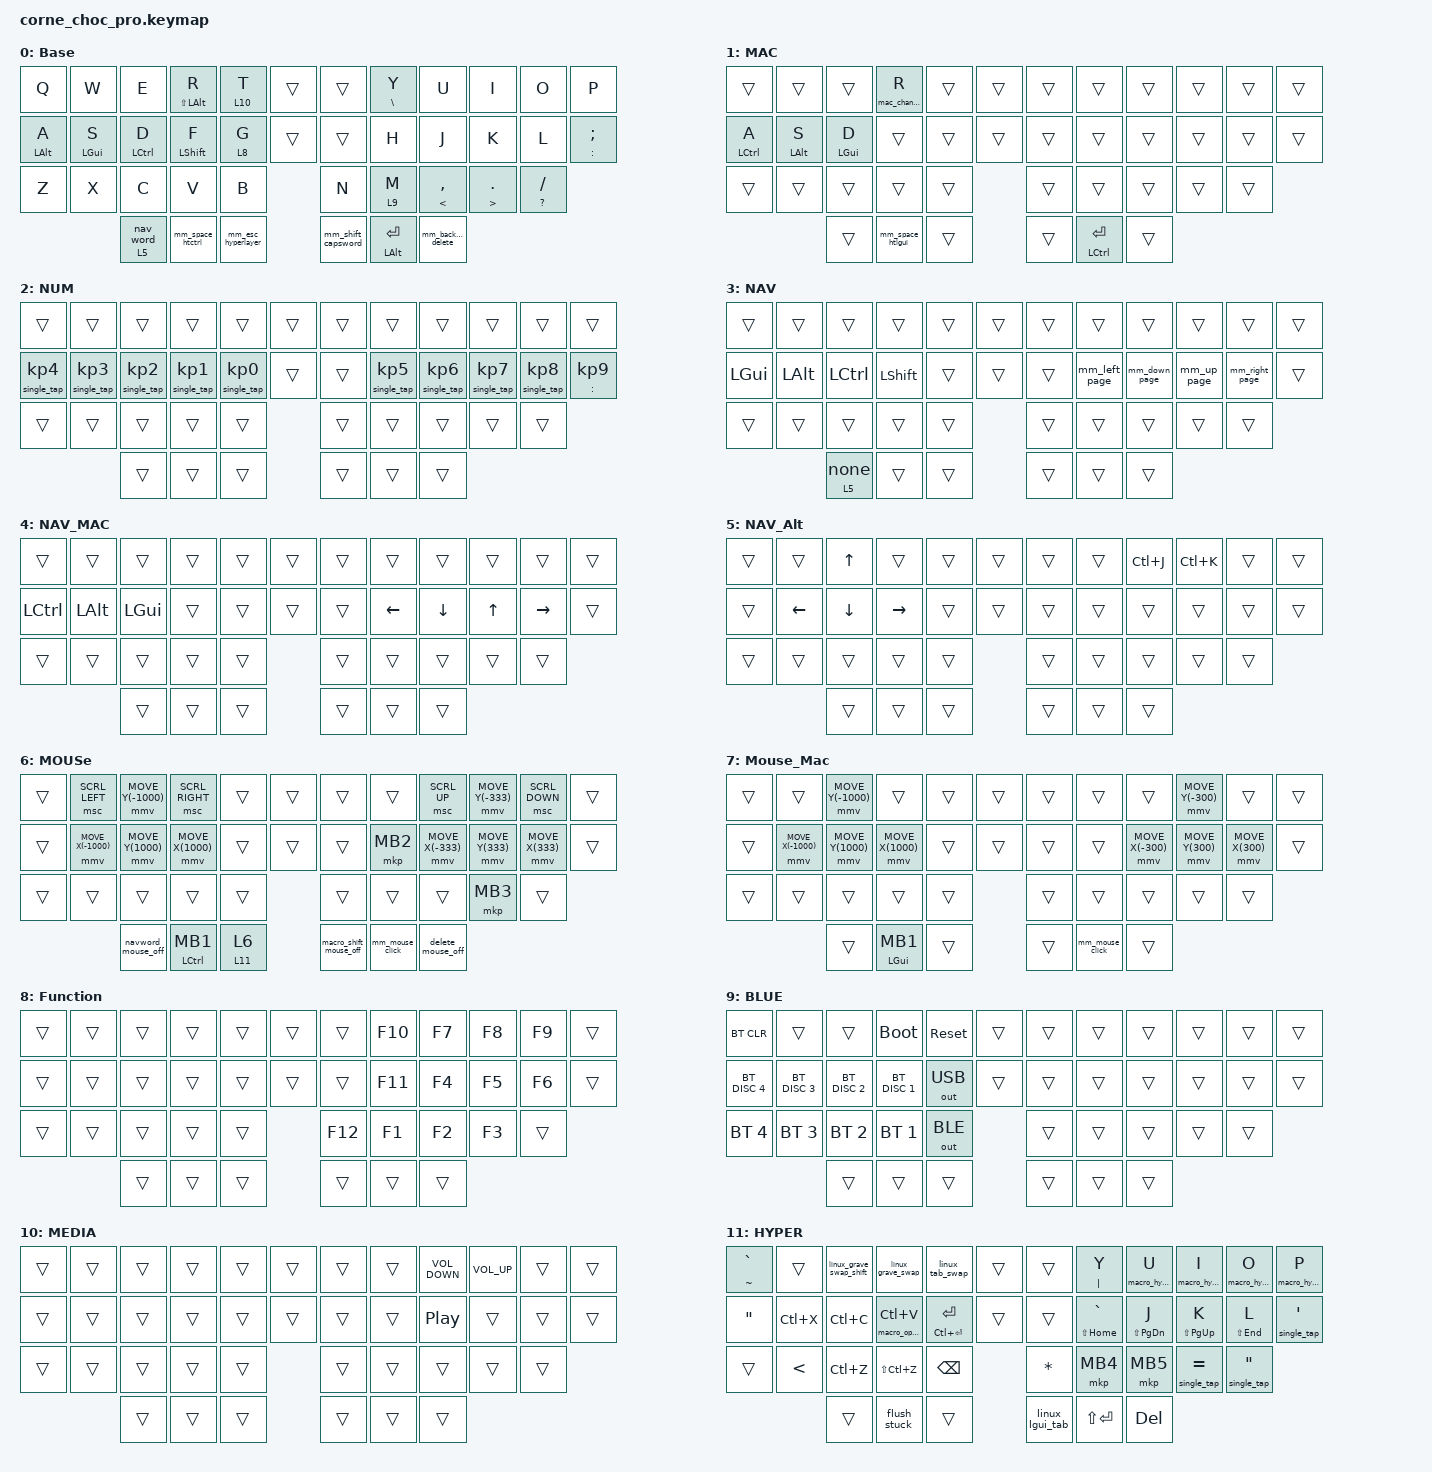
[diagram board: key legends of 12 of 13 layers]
/*
 * Copyright (c) 2020 The ZMK Contributors
 *
 * SPDX-License-Identifier: MIT
 */

#define ZMK_POINTING_DEFAULT_MOVE_VAL 1000  // default: 600
#define ZMK_POINTING_DEFAULT_SCRL_VAL 20    // default: 10
#define NUM 2
#define NAV 3

#include <behaviors.dtsi>
#include <dt-bindings/zmk/bt.h>
#include <dt-bindings/zmk/keys.h>
#include <dt-bindings/zmk/outputs.h>
#include <dt-bindings/zmk/pointing.h>
#include <dt-bindings/zmk/rgb.h>

&sk {
    release-after-ms = <1500>;
    quick-release;
};

&mmv {
    time-to-max-speed-ms = <2>;
    acceleration-exponent = <3>;
};

&msc {
    delay-ms = <0>;
    acceleration-exponent = <3>;
    time-to-max-speed-ms = <1>;
};

/ {
    chosen { zmk,physical-layout = &five_col_layout; };
};

/ {
    macros {
        mouse_mode_color_on: mouse_mode_color {
            compatible = "zmk,behavior-macro";
            #binding-cells = <0>;
            bindings = <&macro_tap>, <&tog 6>;

            label = "MOUSE_MODE_COLOR";
        };

        macro_mo2AndLshft: smart_tab_shift {
            compatible = "zmk,behavior-macro";
            #binding-cells = <0>;
            bindings =
                <&macro_press>,
                <&mo 2 &kp LSHIFT>,
                <&macro_pause_for_release>,
                <&macro_release>,
                <&mo 2 &kp LEFT_SHIFT>;

            label = "SMART_TAB_SHIFT";
        };

        mouse_mode_off: mouse_mode_color_off {
            compatible = "zmk,behavior-macro";
            #binding-cells = <0>;
            bindings = <&macro_tap>, <&tog 6>;

            label = "MOUSE_MODE_COLOR";
        };

        mac_lgui_tab: mac_lgui_tab {
            compatible = "zmk,behavior-macro";
            #binding-cells = <0>;
            bindings =
                <&macro_press>,
                <&kp LEFT_GUI>,
                <&macro_tap>,
                <&kp TAB>,
                <&macro_release>,
                <&kp LEFT_GUI>;

            label = "MAC_LGUI_TAB";
        };

        mac_lgui_tab_double: mac_lgui_tab_double {
            compatible = "zmk,behavior-macro";
            #binding-cells = <0>;
            bindings =
                <&macro_press>,
                <&kp LEFT_GUI>,
                <&macro_tap>,
                <&kp TAB>,
                <&macro_tap>,
                <&kp TAB>,
                <&macro_release>,
                <&kp LEFT_GUI>;

            label = "MAC_LGUI_TAB_DOUBLE";
        };

        mac_lgui_tab_tripple: mac_lgui_tab_tripple {
            compatible = "zmk,behavior-macro";
            #binding-cells = <0>;
            bindings =
                <&macro_press>,
                <&kp LEFT_GUI>,
                <&macro_tap>,
                <&kp TAB>,
                <&macro_tap>,
                <&kp TAB>,
                <&macro_tap>,
                <&kp TAB>,
                <&macro_release>,
                <&kp LEFT_GUI>;

            label = "MAC_LGUI_TAB_TRIPPLE";
        };

        linux_lgui_tab: linux_lgui_tab {
            compatible = "zmk,behavior-macro";
            #binding-cells = <0>;
            bindings =
                <&macro_press>,
                <&kp LALT>,
                <&macro_tap>,
                <&kp TAB>,
                <&macro_release>,
                <&kp LALT>;

            label = "LINUX_LGUI_TAB";
        };

        linux_lgui_tab_double: linux_lgui_tab_double {
            compatible = "zmk,behavior-macro";
            #binding-cells = <0>;
            bindings =
                <&macro_press>,
                <&kp LALT>,
                <&macro_tap>,
                <&kp TAB>,
                <&macro_tap>,
                <&kp TAB>,
                <&macro_release>,
                <&kp LALT>;

            label = "LINUX_LGUI_TAB_DOUBLE";
        };

        linux_lgui_tab_tripple: linux_lgui_tab_tripple {
            compatible = "zmk,behavior-macro";
            #binding-cells = <0>;
            bindings =
                <&macro_press>,
                <&kp LALT>,
                <&macro_tap>,
                <&kp TAB>,
                <&macro_tap>,
                <&kp TAB>,
                <&macro_tap>,
                <&kp TAB>,
                <&macro_release>,
                <&kp LALT>;

            label = "LINUX_LGUI_TAB_TRIPPLE";
        };

        mac_change_language: mac_change_language {
            compatible = "zmk,behavior-macro";
            #binding-cells = <0>;
            bindings = <&kp LC(SPC)>;
            label = "MAC_CHANGE_LANGUAGE";
        };

        macro_open_clipboard: macro_open_clipboard {
            compatible = "zmk,behavior-macro";
            #binding-cells = <0>;
            bindings =
                <&macro_press>,
                <&kp LCTRL &kp LGUI>,
                <&macro_tap>,
                <&kp C>,
                <&macro_release>,
                <&kp LCTRL &kp LGUI>;

            label = "MACRO_OPEN_CLIPBOARD";
        };

        mouse_click_and_off: mouse_click_and_off {
            compatible = "zmk,behavior-macro";
            #binding-cells = <0>;
            bindings =
                <&macro_tap>,
                <&macro_color_off>,
                <&macro_tap>,
                <&mkp MB1 &tog 6>;

            label = "MOUSE_CLICK_AND_OFF";
        };

        macro_color_off: macro_color_off {
            compatible = "zmk,behavior-macro";
            #binding-cells = <0>;
            bindings = <&macro_tap>;
            label = "MACRO_COLOR_OFF";
        };

        macro_mouse_up: macro_mouse_up {
            compatible = "zmk,behavior-macro";
            #binding-cells = <0>;
            bindings =
                <&macro_press>,
                <&mmv MOVE_Y(-300) &sl 0>,
                <&macro_pause_for_release>,
                <&macro_release>,
                <&mmv MOVE_Y(-300) &sl 0>;

            label = "MACRO_MOUSE_UP";
        };

        macro_color_on: macro_color_on {
            compatible = "zmk,behavior-macro";
            #binding-cells = <0>;
            bindings = <&macro_tap>, <&rgb_ug RGB_ON>;

            label = "MACRO_COLOR_ON";
        };

        flush_stuck: flush_stuck {
            compatible = "zmk,behavior-macro";
            #binding-cells = <0>;
            bindings =
                <&macro_release>,
                <&kp LCTRL>,
                <&macro_release>,
                <&kp LEFT_SHIFT>,
                <&macro_release>,
                <&kp LEFT_ALT>,
                <&macro_release>,
                <&kp LEFT_GUI>,
                <&macro_release>,
                <&kp RCTRL>,
                <&macro_release>,
                <&kp RIGHT_SHIFT>,
                <&macro_release>,
                <&kp RIGHT_ALT>,
                <&macro_release>,
                <&kp RIGHT_GUI>;

            label = "FLUSH_STUCK";
        };

        navword_mouse_off: test {
            compatible = "zmk,behavior-macro";
            #binding-cells = <0>;
            bindings = <&macro_tap>, <&tog 6>, <&macro_tap>, <&nav_word>;

            label = "NAVWORD_NOUSE_OFF";
        };

        delete_mouse_off: delete_mouse_off {
            compatible = "zmk,behavior-macro";
            #binding-cells = <0>;
            bindings = <&macro_tap>, <&tog 6>, <&macro_tap>, <&kp BACKSPACE>;

            label = "DELETE_MOUSE_OFF";
        };

        single_tap: single_tap {
            compatible = "zmk,behavior-macro-one-param";
            #binding-cells = <1>;
            bindings =
                <&macro_param_1to1>,
                <&macro_tap>,
                <&kp MACRO_PLACEHOLDER>,
                <&macro_wait_time 200>;

            label = "SINGLE_TAP";
        };

        hyper_and_mouse_off: hyper_and_mouse_off {
            compatible = "zmk,behavior-macro";
            #binding-cells = <0>;
            bindings =
                <&macro_tap>,
                <&tog 6>,
                <&macro_press>,
                <&kp LS(LA(LC(LG(LGUI))))>,
                <&macro_pause_for_release>,
                <&macro_release>,
                <&kp LS(LA(LC(LG(LEFT_GUI))))>,
                <&macro_tap>,
                <&tog 6>;

            label = "HYPER_AND_MOUSE_OFF";
        };

        macro_hold_and_mouse_off: ht_mouse_off {
            compatible = "zmk,behavior-macro-one-param";
            #binding-cells = <1>;
            bindings =
                <&macro_tap>,
                <&tog 6>,
                <&macro_press>,
                <&macro_param_1to1 &kp MACRO_PLACEHOLDER>,
                <&macro_release>,
                <&macro_param_1to1 &kp MACRO_PLACEHOLDER>;

            label = "HT_MOUSE_OFF";
        };

        mm_shift_capsword: mm_shift_capsword {
            compatible = "zmk,behavior-mod-morph";
            label = "MM_SHIFT_CAPSWORD";
            bindings =
                <&ht_sk_shift_capsword LEFT_SHIFT LEFT_SHIFT>,
                <&caps_word>;

            #binding-cells = <0>;
            mods = <(MOD_LSFT)>;
        };

        macro_shift_mouse_off: macro_sticky_and_mouse_off {
            compatible = "zmk,behavior-macro";
            #binding-cells = <0>;
            bindings =
                <&macro_tap>,
                <&tog 6>,
                <&macro_tap>,
                <&mm_shift_capsword>;

            label = "MACRO_STICKY_AND_MOUSE_OFF";
        };

        num_single_tap: num_single_tap {
            compatible = "zmk,behavior-macro-one-param";
            #binding-cells = <1>;
            bindings =
                <&macro_tap>,
                <&num_word &macro_param_1to1>,
                <&macro_tap>,
                <&kp MACRO_PLACEHOLDER>,
                <&macro_wait_time 200>;

            label = "NUM_SINGLE_TAP";
        };

        macro_hyperkey: macro_hyperkey {
            compatible = "zmk,behavior-macro-one-param";
            #binding-cells = <1>;
            bindings =
                <&macro_press>,
                <&kp LS(LA(LC(LG(LGUI)))) &macro_param_1to1>,
                <&macro_tap>,
                <&kp MACRO_PLACEHOLDER>,
                <&macro_pause_for_release>,
                <&macro_release>,
                <&kp LS(LA(LC(LG(LGUI))))>;

            label = "MACRO_HYPERKEY";
        };

        macro_tap_on_release: macro_tap_release {
            compatible = "zmk,behavior-macro-one-param";
            #binding-cells = <1>;
            bindings =
                <&macro_press>,
                <&macro_pause_for_release>,
                <&macro_release>,
                <&macro_tap>,
                <&macro_param_1to1 &kp MACRO_PLACEHOLDER>;

            label = "MACRO_TAP_RELEASE";
        };

        macro_select_line: macro_select_line {
            compatible = "zmk,behavior-macro";
            #binding-cells = <0>;
            bindings =
                <&macro_press>,
                <&kp LGUI>,
                <&macro_tap>,
                <&kp LEFT>,
                <&macro_press>,
                <&kp LSHIFT>,
                <&macro_tap>,
                <&kp RIGHT>,
                <&macro_pause_for_release>,
                <&macro_release>,
                <&kp LEFT_GUI &kp LSHIFT>,
                <&macro_tap>,
                <&kp LG(C)>;

            label = "MACRO_SELECT_LINE";
        };

        macro_mo_nav_heavy_and_tap: macro_mt_and_tap_on_release {
            compatible = "zmk,behavior-macro-one-param";
            #binding-cells = <1>;
            bindings =
                <&macro_press>,
                <&mo 4>,
                <&macro_pause_for_release>,
                <&macro_release>,
                <&mo 4>,
                <&macro_tap>,
                <&macro_param_1to1 &kp MACRO_PLACEHOLDER>;

            label = "MACRO_MT_AND_TAP_ON_RELEASE";
        };
    };

    combos {
        compatible = "zmk,combos";

        combo_toggle_base_mac {
            bindings = <&tog 1>;
            key-positions = <8 9 10>;
            layers = <0 6 1 7>;
        };

        mac_screenshot_clipboard {
            bindings = <&kp LS(LC(LG(NUMBER_4)))>;
            key-positions = <12 24>;
        };

        combo_left_bracket {
            bindings = <&single_tap LEFT_BRACKET>;
            key-positions = <14 15>;
            layers = <0 1>;
        };

        combo_right_bracket {
            bindings = <&single_tap RIGHT_BRACKET>;
            key-positions = <20 21>;
            layers = <0 1 3 4>;
        };

        combo_paren_left {
            bindings = <&single_tap LEFT_PARENTHESIS>;
            key-positions = <15 16>;
            layers = <0 1>;
        };

        combo_parent_right {
            bindings = <&single_tap RIGHT_PARENTHESIS>;
            key-positions = <19 20>;
            layers = <0 1>;
        };

        combo_tog_mouse {
            bindings = <&mouse_mode_color_on>;
            key-positions = <20 9>;
            layers = <0 1 2 8>;
        };

        combo_minus {
            bindings = <&kp MINUS>;
            key-positions = <27 26>;
        };

        mac_screenshot_image {
            bindings = <&kp LS(LG(NUMBER_4))>;
            key-positions = <12 25>;
        };

        combo_underscore {
            bindings = <&kp UNDER>;
            key-positions = <30 31>;
        };

        combo_plus {
            bindings = <&kp PLUS>;
            key-positions = <21 31>;
        };

        tab_combo {
            bindings = <&kp TAB>;
            key-positions = <15 27>;
        };

        combo_tab_shift {
            bindings = <&kp LS(TAB)>;
            key-positions = <20 30>;
        };

        combo_sl_bluetooh {
            bindings = <&sl 9>;
            key-positions = <1 2 3>;
        };

        combo_left_brace {
            bindings = <&single_tap LEFT_BRACE>;
            key-positions = <16 28>;
        };

        combo_right_brace {
            bindings = <&single_tap RIGHT_BRACE>;
            key-positions = <19 29>;
        };

        combo_zero {
            bindings = <&kp KP_NUMBER_0>;
            key-positions = <16 4>;
            layers = <0 1 3 4>;
        };

        combo_one {
            bindings = <&long_combo_th EXCL NUMBER_1>;
            key-positions = <15 3>;
            layers = <0 1 3 4>;
        };

        combo_two {
            bindings = <&long_combo_th AT_SIGN NUMBER_2>;
            key-positions = <14 2>;
            layers = <0 1 3 4>;
        };

        combo_three {
            bindings = <&kp NUMBER_3>;
            key-positions = <13 1>;
            layers = <0 1 3 4>;
        };

        combo_four {
            bindings = <&kp NUMBER_4>;
            key-positions = <12 0>;
            layers = <0 1 3 4>;
        };

        combo_five {
            bindings = <&kp KP_NUMBER_5>;
            key-positions = <19 7>;
            layers = <0 1 2 4>;
        };

        combo_six {
            bindings = <&kp KP_NUMBER_6>;
            key-positions = <20 8>;
            layers = <0 1 2 4>;
        };

        combo_seven {
            bindings = <&kp KP_N7>;
            key-positions = <21 9>;
            layers = <0 1 2 4>;
        };

        combo_8 {
            bindings = <&kp KP_NUMBER_8>;
            key-positions = <22 10>;
            layers = <0 2 4 1>;
        };

        combo_nine {
            bindings = <&kp KP_NUMBER_9>;
            key-positions = <23 11>;
            layers = <0 1 2 4>;
        };

        combo_star {
            bindings = <&kp STAR>;
            key-positions = <22 10>;
            layers = <11 12>;
        };

        combo_ampersand {
            bindings = <&kp AMPERSAND>;
            key-positions = <21 9>;
            layers = <11 12>;
        };

        combo_caret {
            bindings = <&kp CARET>;
            key-positions = <20 8>;
            layers = <11 12>;
        };

        combo_percent {
            bindings = <&kp PERCENT>;
            key-positions = <19 7>;
            layers = <11 12>;
        };

        combo_num_word {
            bindings = <&num_word>;
            key-positions = <15 2>;
            layers = <0 1 2 8 4 6 11>;
        };

        combo_five_hand {
            bindings = <&kp KP_NUMBER_5>;
            key-positions = <16 4>;
            layers = <11 12>;
        };

        combo_six_hand {
            bindings = <&kp KP_N6>;
            key-positions = <15 3>;
            layers = <11 12>;
        };

        combo_seven_hand {
            bindings = <&kp KP_NUMBER_7>;
            key-positions = <2 14>;
            layers = <11 12>;
        };

        combo_eight_hand {
            bindings = <&kp KP_N8>;
            key-positions = <13 1>;
            layers = <11 12>;
        };

        combo_nine_hand {
            bindings = <&kp N9>;
            key-positions = <12 0>;
            layers = <11 12>;
        };
    };

    behaviors {
        ht_kp: ht_kp {
            compatible = "zmk,behavior-hold-tap";
            label = "HT_KP";
            bindings = <&kp>, <&kp>;

            #binding-cells = <2>;
            require-prior-idle-ms = <200>;
            flavor = "tap-preferred";
            tapping-term-ms = <200>;
        };

        long_mo_tp: long_mo_tp {
            compatible = "zmk,behavior-hold-tap";
            label = "LONG_MO_TP";
            bindings = <&mo>, <&kp>;

            #binding-cells = <2>;
            require-prior-idle-ms = <300>;
            tapping-term-ms = <250>;
            flavor = "tap-preferred";
        };

        ht_mo_navword: ht_mo_navword {
            compatible = "zmk,behavior-hold-tap";
            label = "HT_MO_NAVWORD";
            bindings = <&mo>, <&nav_word>;

            #binding-cells = <2>;
            tapping-term-ms = <200>;
            flavor = "balanced";
            hold-trigger-key-positions = <0 1 2 3 4 5 6 14 15 16 17 18 19 20 28 29 30 31 32 33 7 8 9 10 11 12 13>;
        };

        long_th_kp: long_th_kp {
            compatible = "zmk,behavior-hold-tap";
            label = "LONG_TH_KP";
            bindings = <&kp>, <&kp>;

            #binding-cells = <2>;
            require-prior-idle-ms = <300>;
            tapping-term-ms = <250>;
            flavor = "tap-preferred";
        };

        nav_word: nav_word {
            #binding-cells = <0>;
            compatible = "zmk,behavior-num-word";
            layers = <NAV>;
            continue-list = <LEFT DOWN UP RIGHT LSHIFT LGUI LALT LCTRL ENTER J K Z HOME END PG_DN PG_UP>;
            ignore-numbers;
        };

        num_word: num_word {
            compatible = "zmk,behavior-num-word";
            #binding-cells = <0>;
            layers = <NUM>;
            continue-list = <KP_N1 KP_N2 KP_N3 KP_N4 KP_N5 KP_N6 KP_N7 KP_N8 KP_N9 KP_N0 LSHIFT LGUI LALT COLON MINUS PLUS KP_EQUAL DOT BACKSPACE LEFT_ARROW UP_ARROW DOWN_ARROW RIGHT_ARROW>;
            ignore-numbers;
        };

        tab_swap: tab_swap {
            compatible = "zmk,behavior-tri-state";
            label = "TAB_SWAPPER";
            #binding-cells = <0>;
            bindings = <&kt LGUI>, <&kp TAB>, <&kt LGUI>;

            ignored-key-positions = <43>;
        };

        grave_swap: grave_swap {
            compatible = "zmk,behavior-tri-state";
            label = "GRAVE_SWAPPER";
            #binding-cells = <0>;
            bindings = <&kt LGUI>, <&kp GRAVE>, <&kt LGUI>;

            ignored-key-positions = <43>;
        };

        grave_swap_shift: grave_swap_shift {
            compatible = "zmk,behavior-tri-state";
            label = "GRAVE_SWAP_SHIFT";
            #binding-cells = <0>;
            bindings = <&kt LGUI>, <&kp LS(GRAVE)>, <&kt LGUI>;

            ignored-key-positions = <43>;
        };

        linux_grave_swap: linux_grave_swap {
            compatible = "zmk,behavior-tri-state";
            label = "LINUX_GRAVE_SWAPPER";
            #binding-cells = <0>;
            bindings = <&kt LALT>, <&kp GRAVE>, <&kt LALT>;

            ignored-key-positions = <43>;
        };

        linux_grave_swap_shift: linux_grave_swap_shift {
            compatible = "zmk,behavior-tri-state";
            label = "LINUX_GRAVE_SWAP_SHIFT";
            #binding-cells = <0>;
            bindings = <&kt LALT>, <&kp LS(GRAVE)>, <&kt LALT>;

            ignored-key-positions = <43>;
        };

        linux_tab_swap: linux_tab_swap {
            compatible = "zmk,behavior-tri-state";
            label = "LINUX_TAB_SWAP";
            #binding-cells = <0>;
            bindings = <&kt LALT>, <&kp TAB>, <&kt LALT>;

            ignored-key-positions = <43>;
        };

        mm_space_htctrl: mm_space_htctrl {
            compatible = "zmk,behavior-mod-morph";
            label = "MM_SPACE_HTCTRL";
            bindings = <&ht_kp LCTRL SPACE>, <&kp LS(LCTRL)>;

            #binding-cells = <0>;
            mods = <(MOD_LSFT)>;
            keep-mods = <(MOD_LSFT)>;
        };

        mm_space_htlgui: mm_space_htlgui {
            compatible = "zmk,behavior-mod-morph";
            label = "MM_SPACE_HTLGUI";
            bindings = <&ht_kp LGUI SPACE>, <&kp LS(LGUI)>;

            #binding-cells = <0>;
            mods = <(MOD_LSFT)>;
            keep-mods = <(MOD_LSFT)>;
        };

        ht_kp_mb1_and_off: ht_kp_mb1_and_off {
            compatible = "zmk,behavior-hold-tap";
            label = "HT_KP_MB1_AND_OFF";
            bindings = <&macro_hold_and_mouse_off>, <&mouse_click_and_off>;

            #binding-cells = <2>;
            quick-tap-ms = <0>;
            tapping-term-ms = <200>;
            flavor = "tap-preferred";
        };

        mm_mouse_click: mm_mouse_click {
            compatible = "zmk,behavior-mod-morph";
            label = "MM_MOUSE_CLICK";
            bindings = <&mkp MB1>, <&kp LG(ENTER)>;

            #binding-cells = <0>;
            mods = <(MOD_LGUI)>;
        };

        ht_kp_kp: ht_kp_kp {
            compatible = "zmk,behavior-hold-tap";
            label = "HT_KP_KP";
            bindings = <&kp>, <&kp>;

            #binding-cells = <2>;
            require-prior-idle-ms = <200>;
            flavor = "tap-preferred";
            tapping-term-ms = <175>;
        };

        mm_backspace_delete: mm_backspace_delete {
            compatible = "zmk,behavior-mod-morph";
            label = "MM_BACKSPACE_DELETE";
            bindings = <&kp BACKSPACE>, <&kp DELETE>;

            #binding-cells = <0>;
            mods = <(MOD_LSFT)>;
        };

        ht_single_tap: ht_single_tap {
            compatible = "zmk,behavior-hold-tap";
            label = "HT_SINGLE_TAP";
            bindings = <&single_tap>, <&kp>;

            #binding-cells = <2>;
            tapping-term-ms = <175>;
            flavor = "tap-preferred";
        };

        ht_hyper_and_mouse: ht_hyper_and_mouse {
            compatible = "zmk,behavior-hold-tap";
            label = "HT_HYPER_AND_MOUSE";
            bindings = <&mo>, <&tog>;

            #binding-cells = <2>;
            hold-trigger-key-positions = <7 8 9 10 11 12 13 21 22 23 24 25 26 27 34 35 36 37 38 39>;
            flavor = "balanced";
            hold-while-undecided;
            tapping-term-ms = <175>;
        };

        ht_maclanguage_r: ht_maclanguage_r {
            compatible = "zmk,behavior-hold-tap";
            label = "HT_MACLANGUAGE_R";
            bindings = <&mac_change_language>, <&kp>;

            #binding-cells = <2>;
            tapping-term-ms = <175>;
            flavor = "tap-preferred";
        };

        mm_esc_hyperlayer: mm_esc_hyperlayer {
            compatible = "zmk,behavior-mod-morph";
            label = "MM_ESC_HYPERLAYER";
            bindings = <&ht_mo_eagor_trigger 11 ESCAPE>, <&kp F20>;

            #binding-cells = <0>;
            mods = <(MOD_LSFT)>;
        };

        ht_num_single_tap: ht_num_single_tap {
            compatible = "zmk,behavior-hold-tap";
            label = "HT_NUM_SINGLE_TAP";
            bindings = <&num_single_tap>, <&kp>;

            #binding-cells = <2>;
            tapping-term-ms = <200>;
            flavor = "tap-preferred";
        };

        ht_sk_shift_capsword: ht_sk_shift_capsword {
            compatible = "zmk,behavior-hold-tap";
            label = "HT_SK_SHIFT_CAPSWORD";
            bindings = <&kp>, <&sk>;

            #binding-cells = <2>;
            tapping-term-ms = <200>;
            flavor = "tap-preferred";
            hold-trigger-key-positions = <1 2 3 4 5 15 16 17 18 19 29 30 31 32 33>;
        };

        ht_num_single_tap_weak: ht_num_single_tap_weak {
            compatible = "zmk,behavior-hold-tap";
            label = "HT_NUM_SINGLE_TAP_WEAK";
            bindings = <&num_single_tap>, <&kp>;

            #binding-cells = <2>;
            tapping-term-ms = <275>;
            flavor = "tap-preferred";
        };

        ht_single_tap_weak: ht_single_tap_weak {
            compatible = "zmk,behavior-hold-tap";
            label = "HT_SINGLE_TAP_WEAK";
            bindings = <&single_tap>, <&kp>;

            #binding-cells = <2>;
            tapping-term-ms = <275>;
            flavor = "tap-preferred";
        };

        ht_mo_eagor_trigger: ht_mo_eagor_trigger {
            compatible = "zmk,behavior-hold-tap";
            label = "HT_MO_EAGOR_TRIGGER";
            bindings = <&mo>, <&kp>;

            #binding-cells = <2>;
            hold-trigger-key-positions = <7 8 9 10 11 12 13 21 22 23 24 25 26 27 34 35 36 37 38 39 43 44 45 0 1 2 3 4 5 6 14 15 16 17 18 19 20 28 29 30 31 32 33 41 40>;
            hold-while-undecided;
            flavor = "balanced";
            tapping-term-ms = <200>;
        };

        ht_clipboard: ht_clipboard {
            compatible = "zmk,behavior-hold-tap";
            label = "HT_CLIPBOARD";
            bindings = <&macro_open_clipboard>, <&kp>;

            #binding-cells = <2>;
            tapping-term-ms = <200>;
            flavor = "balanced";
        };

        ht_macro_hyperkey: ht_macro_hyperkey {
            compatible = "zmk,behavior-hold-tap";
            label = "HT_MACRO_HYPERKEY";
            bindings = <&single_tap>, <&macro_hyperkey>;

            #binding-cells = <2>;
            tapping-term-ms = <200>;
            flavor = "tap-preferred";
        };

        ht_select_line_mac: ht_select_line_mac {
            compatible = "zmk,behavior-hold-tap";
            label = "HT_SELECT_LINE_MAC";
            bindings = <&macro_select_line>, <&kp>;

            #binding-cells = <2>;
            tapping-term-ms = <200>;
            flavor = "tap-preferred";
        };

        mm_left_page: mm_left_page {
            compatible = "zmk,behavior-mod-morph";
            label = "MM_LEFT_PAGE";
            bindings = <&kp LEFT>, <&kp HOME>;

            #binding-cells = <0>;
            mods = <(MOD_LCTL)>;
        };

        mm_down_page: mm_down_page {
            compatible = "zmk,behavior-mod-morph";
            label = "MM_DOWN_PAGE";
            bindings = <&kp DOWN>, <&kp PAGE_DOWN>;

            #binding-cells = <0>;
            mods = <(MOD_LCTL)>;
        };

        mm_up_page: mm_up_page {
            compatible = "zmk,behavior-mod-morph";
            label = "MM_UP_PAGE";
            bindings = <&kp UP_ARROW>, <&kp PAGE_UP>;

            #binding-cells = <0>;
            mods = <(MOD_LCTL)>;
        };

        mm_right_page: mm_right_page {
            compatible = "zmk,behavior-mod-morph";
            label = "MM_RIGHT_PAGE";
            bindings = <&kp RIGHT>, <&kp END>;

            #binding-cells = <0>;
            mods = <(MOD_LCTL)>;
        };

        mm_mo_hold: mm_mo_hold {
            compatible = "zmk,behavior-hold-tap";
            label = "MM_MO_HOLD";
            bindings = <&mo>, <&none>;

            #binding-cells = <2>;
            flavor = "balanced";
            hold-trigger-key-positions = <7 8>;
            tapping-term-ms = <175>;
        };

        long_combo_th: long_combo_th {
            compatible = "zmk,behavior-hold-tap";
            label = "LONG_COMBO_TH";
            bindings = <&single_tap>, <&kp>;

            #binding-cells = <2>;
            require-prior-idle-ms = <0>;
            tapping-term-ms = <250>;
            flavor = "tap-preferred";
        };

        really_long_mo_ht: really_long_mo_ht {
            compatible = "zmk,behavior-hold-tap";
            label = "REALLY_LONG_MO_HT";
            bindings = <&mo>, <&kp>;

            #binding-cells = <2>;
            require-prior-idle-ms = <300>;
            tapping-term-ms = <350>;
            flavor = "tap-preferred";
        };
    };

    keymap {
        compatible = "zmk,keymap";

        BASE {
            display-name = "Base";
            bindings = <
  &kp Q  &kp W  &kp E  &ht_kp_kp LS(LEFT_ALT) R  &long_mo_tp 10 T  &trans  &trans  &ht_single_tap BACKSLASH Y  &kp U  &kp I  &kp O  &kp P
  &long_th_kp LALT A  &long_th_kp LGUI S  &long_th_kp LCTRL D  &long_th_kp LSHFT F  &long_mo_tp 8 G  &trans  &trans  &kp H  &kp J  &kp K  &kp L  &ht_single_tap COLON SEMI
  &kp Z               &kp X               &kp C                &kp V                     &kp B                   &kp N                       &long_mo_tp 9 M  &ht_single_tap LESS_THAN COMMA  &ht_single_tap_weak GREATER_THAN DOT  &ht_num_single_tap_weak QUESTION FSLH
                                          &ht_mo_navword 5 0   &mm_space_htctrl          &mm_esc_hyperlayer      &mm_shift_capsword          &mt LALT ENTER   &mm_backspace_delete
            >;
        };

        MAC {
            bindings = <
  &trans  &trans  &trans  &ht_maclanguage_r 0 R  &trans  &trans  &trans  &trans  &trans  &trans  &trans  &trans
  &long_th_kp LCTRL A  &long_th_kp LALT S  &long_th_kp LGUI D  &trans  &trans  &trans  &trans  &trans  &trans  &trans  &trans  &trans
  &trans               &trans              &trans              &trans                 &trans      &trans  &trans           &trans  &trans  &trans
                                           &trans              &mm_space_htlgui       &trans      &trans  &mt LCTRL ENTER  &trans
            >;

            label = "MAC";
        };

        NUM {
            display-name = "NUM";
            bindings = <
  &trans  &trans  &trans  &trans  &trans  &trans  &trans  &trans  &trans  &trans  &trans  &trans
  &single_tap KP_NUMBER_4  &single_tap KP_NUMBER_3  &single_tap KP_NUMBER_2  &single_tap KP_NUMBER_1  &single_tap KP_NUMBER_0  &trans  &trans  &single_tap KP_NUMBER_5  &single_tap KP_N6  &single_tap KP_N7  &single_tap KP_NUMBER_8  &ht_single_tap_weak COLON KP_NUMBER_9
  &trans                   &trans                   &trans                   &trans                   &trans                       &trans                   &trans             &trans             &trans                   &trans
                                                    &trans                   &trans                   &trans                       &trans                   &trans             &trans
            >;
        };

        NAV {
            display-name = "NAV";
            bindings = <
  &trans  &trans  &trans  &trans  &trans  &trans  &trans  &trans  &trans  &trans  &trans  &trans
  &kp LGUI  &kp LEFT_ALT  &kp LCTRL  &kp LEFT_SHIFT  &trans  &trans  &trans  &mm_left_page  &mm_down_page  &mm_up_page  &mm_right_page  &trans
  &trans    &trans        &trans           &trans          &trans      &trans         &trans         &trans       &trans          &trans
                          &mm_mo_hold 5 0  &trans          &trans      &trans         &trans         &trans
            >;
        };

        NAV_MAC {
            bindings = <
  &trans  &trans  &trans  &trans  &trans  &trans  &trans  &trans  &trans  &trans  &trans  &trans
  &kp LCTRL  &kp LEFT_ALT  &kp LGUI  &trans  &trans  &trans  &trans  &kp LEFT  &kp DOWN  &kp UP_ARROW  &kp RIGHT  &trans
  &trans     &trans        &trans    &trans  &trans      &trans    &trans    &trans        &trans     &trans
                           &trans    &trans  &trans      &trans    &trans    &trans
            >;

            label = "NAV_MAC";
        };

        NAV_ALT {
            label = "NAV_Alt";
            bindings = <
  &trans  &trans  &kp UP_ARROW  &trans  &trans  &trans  &trans  &trans  &kp LC(J)  &kp LC(K)  &trans  &trans
  &trans  &kp LEFT  &kp DOWN  &kp RIGHT  &trans  &trans  &trans  &trans  &trans  &trans  &trans  &trans
  &trans  &trans    &trans        &trans     &trans      &trans  &trans     &trans     &trans  &trans
                    &trans        &trans     &trans      &trans  &trans     &trans
            >;
        };

        mouse {
            bindings = <
  &trans  &msc SCRL_LEFT  &mmv MOVE_Y(-1000)  &msc SCRL_RIGHT  &trans  &trans  &trans  &trans  &msc SCRL_UP  &mmv MOVE_Y(-333)  &msc SCRL_DOWN  &trans
  &trans  &mmv MOVE_X(-1000)  &mmv MOVE_Y(1000)  &mmv MOVE_X(1000)  &trans  &trans  &trans  &mkp MB2  &mmv MOVE_X(-333)  &mmv MOVE_Y(333)  &mmv MOVE_X(333)  &trans
  &trans  &trans              &trans              &trans                        &trans                        &trans                  &trans             &trans             &mkp MB3          &trans
                              &navword_mouse_off  &ht_kp_mb1_and_off LCTRL MB1  &ht_hyper_and_mouse 11 6      &macro_shift_mouse_off  &mm_mouse_click    &delete_mouse_off
            >;

            label = "MOUSe";
        };

        mouse_mac {
            bindings = <
  &trans  &trans  &mmv MOVE_Y(-1000)  &trans  &trans  &trans  &trans  &trans  &trans  &mmv MOVE_Y(-300)  &trans  &trans
  &trans  &mmv MOVE_X(-1000)  &mmv MOVE_Y(1000)  &mmv MOVE_X(1000)  &trans  &trans  &trans  &trans  &mmv MOVE_X(-300)  &mmv MOVE_Y(300)  &mmv MOVE_X(300)  &trans
  &trans  &trans              &trans              &trans                       &trans      &trans  &trans             &trans             &trans            &trans
                              &trans              &ht_kp_mb1_and_off LGUI MB1  &trans      &trans  &mm_mouse_click    &trans
            >;

            label = "Mouse_Mac";
        };

        Function {
            bindings = <
  &trans  &trans  &trans  &trans  &trans  &trans  &trans  &kp F10  &kp F7  &kp F8  &kp F9  &trans
  &trans  &trans  &trans  &trans  &trans  &trans  &trans  &kp F11  &kp F4  &kp F5  &kp F6  &trans
  &trans  &trans  &trans  &trans  &trans      &kp F12  &kp F1  &kp F2  &kp F3  &trans
                  &trans  &trans  &trans      &trans   &trans  &trans
            >;

            label = "Function";
        };

        BLUE {
            bindings = <
  &bt BT_CLR  &trans  &trans  &bootloader  &sys_reset  &trans  &trans  &trans  &trans  &trans  &trans  &trans
  &bt BT_DISC 4  &bt BT_DISC 3  &bt BT_DISC 2  &bt BT_DISC 1  &out OUT_USB  &trans  &trans  &trans  &trans  &trans  &trans  &trans
  &bt BT_SEL 4   &bt BT_SEL 3   &bt BT_SEL 2   &bt BT_SEL 1   &out OUT_BLE      &trans  &trans  &trans  &trans  &trans
                                &trans         &trans         &trans            &trans  &trans  &trans
            >;

            label = "BLUE";
        };

        MEDIA {
            bindings = <
  &trans  &trans  &trans  &trans  &trans  &trans  &trans  &trans  &kp C_VOLUME_DOWN  &kp C_VOLUME_UP  &trans  &trans
  &trans  &trans  &trans  &trans  &trans  &trans  &trans  &trans  &kp C_PP  &trans  &trans  &trans
  &trans  &trans  &trans  &trans  &trans      &trans  &trans             &trans           &trans  &trans
                  &trans  &trans  &trans      &trans  &trans             &trans
            >;

            label = "MEDIA";
        };

        HYPER {
            bindings = <
  &ht_single_tap TILDE GRAVE  &trans  &linux_grave_swap_shift  &linux_grave_swap  &linux_tab_swap  &trans  &trans  &ht_macro_hyperkey PIPE Y  &macro_hyperkey U  &macro_hyperkey I  &macro_hyperkey O  &macro_hyperkey P
  &kp DOUBLE_QUOTES  &kp LC(X)  &kp LC(C)  &ht_clipboard 0 LC(V)  &ht_single_tap LC(ENTER) ENTER  &trans  &trans  &ht_single_tap LS(HOME) GRAVE  &ht_macro_hyperkey LS(PAGE_DOWN) J  &ht_macro_hyperkey LS(PG_UP) K  &ht_macro_hyperkey LS(END) L  &single_tap SINGLE_QUOTE
  &trans                      &kp LESS_THAN  &kp LC(Z)                &kp LS(LC(Z))          &kp BACKSPACE                       &kp STAR                       &mkp MB4                            &mkp MB5                        &single_tap EQUAL             &single_tap DOUBLE_QUOTES
                                             &trans                   &flush_stuck           &trans                              &linux_lgui_tab                &kp LS(ENTER)                       &kp DELETE
            >;

            label = "HYPER";
        };

        HYPER_MAC {
            bindings = <
  &trans  &trans  &grave_swap_shift  &grave_swap  &tab_swap  &trans  &trans  &trans  &trans  &trans  &trans  &trans
  &trans  &kp LG(X)  &ht_select_line_mac 0 LG(C)  &ht_clipboard 0 LG(V)  &ht_single_tap LG(ENTER) ENTER  &trans  &trans  &ht_single_tap LG(LS(LEFT)) GRAVE  &ht_macro_hyperkey LS(LG(DOWN)) J  &ht_macro_hyperkey LS(LG(UP_ARROW)) K  &ht_macro_hyperkey LS(LG(RIGHT)) L  &trans
  &trans  &trans     &kp LG(Z)                    &kp LS(LG(Z))          &trans                              &trans                             &trans                             &trans                                 &trans                              &trans
                     &trans                       &trans                 &trans                              &mac_lgui_tab                      &trans                             &trans
            >;

            label = "HYPER_MAC";
        };
    };

    conditional_layers {
        compatible = "zmk,conditional-layers";

        mouse_mac_activate_mouse {
            if-layers = <1 6>;
            then-layer = <7>;
        };

        macro_layer_hyper_one_hand {
            if-layers = <1 11>;
            then-layer = <12>;
        };

        nav {
            if-layers = <1 3>;
            then-layer = <4>;
        };
    };
};
